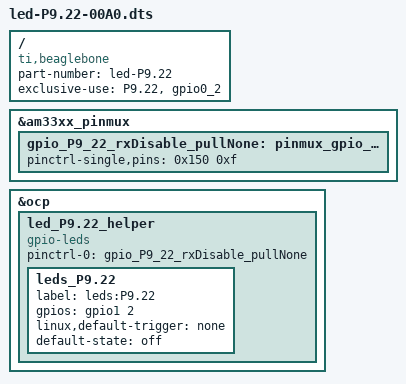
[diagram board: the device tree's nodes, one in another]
/*
* Easy gpio mux control of "P9.22" ("gpio0_2")
*/
/dts-v1/;
/plugin/;

/ {
	compatible = "ti,beaglebone", "ti,beaglebone-black";

	/* identification */
	part-number = "led-P9.22";
	/* version = "00A0"; */

	/* state the resources this cape uses */
	exclusive-use =
		/* the pin header uses */
		"P9.22",

		/* the hardware IP uses */
		"gpio0_2";
	
	
	/* rxDisable_pullNone state */
	fragment@0 {
		target = <&am33xx_pinmux>;
		__overlay__ {
			gpio_P9_22_rxDisable_pullNone: pinmux_gpio_P9.22_rxDisable_pullNone {
				pinctrl-single,pins = <
					0x150 0xf
				>;
			};
		};
	};

	fragment@1 {
		target = <&ocp>;
		__overlay__ {
			led_P9.22_helper {
				compatible = "gpio-leds";
				pinctrl-names = "default";
				pinctrl-0 = <&gpio_P9_22_rxDisable_pullNone>;
				
				leds_P9.22 {
					label = "leds:P9.22";
					gpios = <&gpio1 2 0>;
					linux,default-trigger = "none";
					default-state = "off";
				};
			};
			
		};
	};

};
